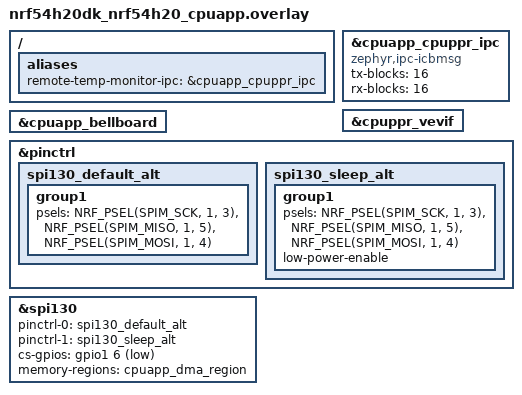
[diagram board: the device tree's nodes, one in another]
/*
 * Copyright (c) 2026 Nordic Semiconductor ASA
 *
 * SPDX-License-Identifier: LicenseRef-Nordic-5-Clause
 */

/ {
	aliases {
		/*/delete-property/ led0;*/
		remote-temp-monitor-ipc = &cpuapp_cpuppr_ipc;
	};
};

/*/delete-node/ &led0;*/

&cpuapp_cpuppr_ipc {
	status = "okay";
	compatible = "zephyr,ipc-icbmsg";
	tx-blocks = <16>;
	rx-blocks = <16>;
};

&cpuppr_vevif {
	status = "okay";
};

&cpuapp_bellboard {
	status = "okay";
};

&pinctrl {
	spi130_default_alt: spi130_default_alt {
		group1 {
			psels = <NRF_PSEL(SPIM_SCK, 1, 3)>,
				<NRF_PSEL(SPIM_MISO, 1, 5)>,
				<NRF_PSEL(SPIM_MOSI, 1, 4)>;
		};
	};

	spi130_sleep_alt: spi130_sleep_alt {
		group1 {
			psels = <NRF_PSEL(SPIM_SCK, 1, 3)>,
				<NRF_PSEL(SPIM_MISO, 1, 5)>,
				<NRF_PSEL(SPIM_MOSI, 1, 4)>;
			low-power-enable;
		};
	};
};

app_spi: &spi130 {
	status = "okay";
	pinctrl-0 = <&spi130_default_alt>;
	pinctrl-1 = <&spi130_sleep_alt>;
	pinctrl-names = "default", "sleep";
	cs-gpios = <&gpio1 6 GPIO_ACTIVE_LOW>;
	memory-regions = <&cpuapp_dma_region>;
};
